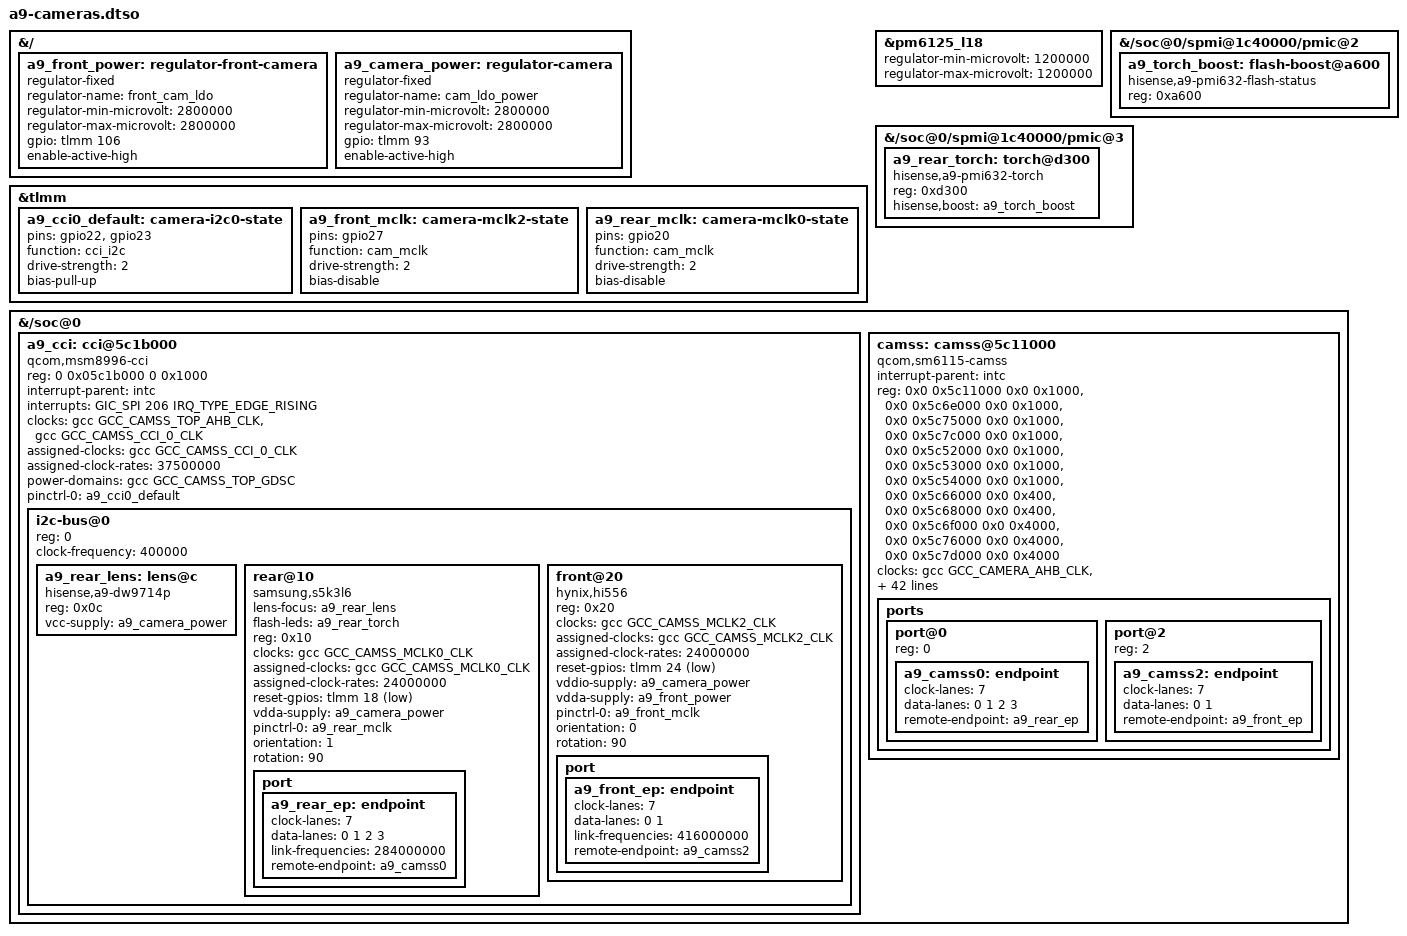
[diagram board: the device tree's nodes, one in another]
// SPDX-License-Identifier: GPL-2.0-only
/dts-v1/;
/plugin/;
#include <dt-bindings/clock/qcom,gcc-sm6115.h>
#include <dt-bindings/gpio/gpio.h>
#include <dt-bindings/interrupt-controller/arm-gic.h>
#include <dt-bindings/interconnect/qcom,sm6115.h>
#include <dt-bindings/interconnect/qcom,rpm-icc.h>

/* Default dual-sensor graph. A9_FRONT_PROBE/A9_REAR_ONLY select isolated graphs.
 * CAMSS 3PH/14nm DPHY uses data lanes 0..3 and the dedicated clock lane 7.
 * csid_get_lane_assign() consumes these positions directly (rear 0x3210).
 */
&{/} {
#ifndef A9_REAR_ONLY
 a9_front_power: regulator-front-camera {
  compatible = "regulator-fixed";
  regulator-name = "front_cam_ldo";
  /* GPIO106 supplies both analogue 2.8V and core 1.2V. */
  regulator-min-microvolt = <2800000>;
  regulator-max-microvolt = <2800000>;
  gpio = <&tlmm 106 GPIO_ACTIVE_HIGH>;
  enable-active-high;
 };
#endif
	a9_camera_power: regulator-camera {
		compatible = "regulator-fixed";
		regulator-name = "cam_ldo_power";
		/* External LDO bank supplies 1.8V I/O, 2.8V analogue/AF, 1.05V core. */
		regulator-min-microvolt = <2800000>;
		regulator-max-microvolt = <2800000>;
		gpio = <&tlmm 93 GPIO_ACTIVE_HIGH>;
		enable-active-high;
	};
};

&tlmm {
	a9_cci0_default: camera-i2c0-state {
		pins = "gpio22", "gpio23";
		function = "cci_i2c";
		drive-strength = <2>;
		bias-pull-up;
	};
	a9_front_mclk: camera-mclk2-state {
  pins = "gpio27";
  function = "cam_mclk";
  drive-strength = <2>;
  bias-disable;
 };
 a9_rear_mclk: camera-mclk0-state {
		pins = "gpio20";
		function = "cam_mclk";
		drive-strength = <2>;
		bias-disable;
	};
};

/* Stock PHY rail: PM6125 L18, camera consumer requests 1.2V. */
&pm6125_l18 {
	regulator-min-microvolt = <1200000>;
	regulator-max-microvolt = <1200000>;
};

#ifndef A9_FRONT_PROBE
&{/soc@0/spmi@1c40000/pmic@2} {
 #address-cells = <1>;
 #size-cells = <0>;
 a9_torch_boost: flash-boost@a600 {
  compatible = "hisense,a9-pmi632-flash-status";
  reg = <0xa600>;
 };
};
&{/soc@0/spmi@1c40000/pmic@3} {
 #address-cells = <1>;
 #size-cells = <0>;
 a9_rear_torch: torch@d300 {
  compatible = "hisense,a9-pmi632-torch";
  reg = <0xd300>;
  hisense,boost = <&a9_torch_boost>;
  status = "okay";
 };
};
#endif

&{/soc@0} {
	#address-cells = <2>;
	#size-cells = <2>;
	a9_cci: cci@5c1b000 {
		compatible = "qcom,msm8996-cci";
		reg = <0 0x05c1b000 0 0x1000>;
		interrupt-parent = <&intc>;
		interrupts = <GIC_SPI 206 IRQ_TYPE_EDGE_RISING>;
		clocks = <&gcc GCC_CAMSS_TOP_AHB_CLK>, <&gcc GCC_CAMSS_CCI_0_CLK>;
		clock-names = "ahb", "cci";
		assigned-clocks = <&gcc GCC_CAMSS_CCI_0_CLK>;
		assigned-clock-rates = <37500000>;
		power-domains = <&gcc GCC_CAMSS_TOP_GDSC>;
		pinctrl-names = "default";
		pinctrl-0 = <&a9_cci0_default>;
		#address-cells = <1>;
		#size-cells = <0>;
		status = "okay";
		i2c-bus@0 {
			reg = <0>;
			clock-frequency = <400000>;
			#address-cells = <1>;
			#size-cells = <0>;
#ifndef A9_FRONT_PROBE
   a9_rear_lens: lens@c {
    compatible = "hisense,a9-dw9714p";
    reg = <0x0c>;
    vcc-supply = <&a9_camera_power>;
   };
			rear@10 {
				compatible = "samsung,s5k3l6";
                lens-focus = <&a9_rear_lens>;
                flash-leds = <&a9_rear_torch>;
				reg = <0x10>;
				clocks = <&gcc GCC_CAMSS_MCLK0_CLK>;
				assigned-clocks = <&gcc GCC_CAMSS_MCLK0_CLK>;
				assigned-clock-rates = <24000000>;
				reset-gpios = <&tlmm 18 GPIO_ACTIVE_LOW>;
				vdda-supply = <&a9_camera_power>;
				pinctrl-names = "default";
				pinctrl-0 = <&a9_rear_mclk>;
				/* V4L2 front=0, back=1; the DT property wins over HAL YAML. */
				orientation = <1>;
				/* Linux CCW90 -> Android CW270, matching stock rear roll270. */
				rotation = <90>;
				port {
					a9_rear_ep: endpoint {
						clock-lanes = <7>;
						data-lanes = <0 1 2 3>;
						link-frequencies = /bits/ 64 <284000000>;
						remote-endpoint = <&a9_camss0>;
					};
				};
			};
#endif
#ifndef A9_REAR_ONLY
			front@20 {
				compatible = "hynix,hi556";
				reg = <0x20>;
				clocks = <&gcc GCC_CAMSS_MCLK2_CLK>;
				assigned-clocks = <&gcc GCC_CAMSS_MCLK2_CLK>;
				assigned-clock-rates = <24000000>;
				reset-gpios = <&tlmm 24 GPIO_ACTIVE_LOW>;
				vddio-supply = <&a9_camera_power>;
				vdda-supply = <&a9_front_power>;
				pinctrl-names = "default";
				pinctrl-0 = <&a9_front_mclk>;
				/* Front=0; Linux CCW90 gives stock Android CW270. */
				orientation = <0>;
				rotation = <90>;
				port {
					a9_front_ep: endpoint {
						clock-lanes = <7>;
						data-lanes = <0 1>;
						/* Derived from stock OP pixel rate, needs hardware proof. */
						link-frequencies = /bits/ 64 <416000000>;
						remote-endpoint = <&a9_camss2>;
					};
				};
			};
#endif
		};
	};
		camss: camss@5c11000 {
			compatible = "qcom,sm6115-camss";
			interrupt-parent = <&intc>;

			reg = <0x0 0x5c11000 0x0 0x1000>,
			      <0x0 0x5c6e000 0x0 0x1000>,
			      <0x0 0x5c75000 0x0 0x1000>,
			      <0x0 0x5c7c000 0x0 0x1000>,
			      <0x0 0x5c52000 0x0 0x1000>,
			      <0x0 0x5c53000 0x0 0x1000>,
			      <0x0 0x5c54000 0x0 0x1000>,
			      <0x0 0x5c66000 0x0 0x400>,
			      <0x0 0x5c68000 0x0 0x400>,
			      <0x0 0x5c6f000 0x0 0x4000>,
			      <0x0 0x5c76000 0x0 0x4000>,
			      <0x0 0x5c7d000 0x0 0x4000>;
			reg-names = "top", "csid0", "csid1", "csid2",
			    "csiphy0", "csiphy1", "csiphy2", "csitpg0", "csitpg1",
			    "vfe0", "vfe1", "vfe2";

			clocks = <&gcc GCC_CAMERA_AHB_CLK>,
				 <&gcc GCC_CAMSS_AXI_CLK>,
				 <&gcc GCC_CAMSS_NRT_AXI_CLK>,
				 <&gcc GCC_CAMSS_RT_AXI_CLK>,
				 <&gcc GCC_CAMSS_TFE_0_CSID_CLK>,
				 <&gcc GCC_CAMSS_TFE_1_CSID_CLK>,
				 <&gcc GCC_CAMSS_TFE_2_CSID_CLK>,
				 <&gcc GCC_CAMSS_CPHY_0_CLK>,
				 <&gcc GCC_CAMSS_CSI0PHYTIMER_CLK>,
				 <&gcc GCC_CAMSS_CPHY_1_CLK>,
				 <&gcc GCC_CAMSS_CSI1PHYTIMER_CLK>,
				 <&gcc GCC_CAMSS_CPHY_2_CLK>,
				 <&gcc GCC_CAMSS_CSI2PHYTIMER_CLK>,
				 <&gcc GCC_CAMSS_TOP_AHB_CLK>,
				 <&gcc GCC_CAMSS_TFE_0_CLK>,
				 <&gcc GCC_CAMSS_TFE_0_CPHY_RX_CLK>,
				 <&gcc GCC_CAMSS_TFE_1_CLK>,
				 <&gcc GCC_CAMSS_TFE_1_CPHY_RX_CLK>,
				 <&gcc GCC_CAMSS_TFE_2_CLK>,
				 <&gcc GCC_CAMSS_TFE_2_CPHY_RX_CLK>;
			clock-names = "ahb", "axi", "camnoc_nrt_axi", "camnoc_rt_axi",
			      "csi0", "csi1", "csi2", "csiphy0", "csiphy0_timer",
			      "csiphy1", "csiphy1_timer", "csiphy2", "csiphy2_timer",
			      "top_ahb", "vfe0", "vfe0_cphy_rx", "vfe1", "vfe1_cphy_rx",
			      "vfe2", "vfe2_cphy_rx";

			interrupts = <GIC_SPI 210 IRQ_TYPE_EDGE_RISING>,
				     <GIC_SPI 212 IRQ_TYPE_EDGE_RISING>,
				     <GIC_SPI 77 IRQ_TYPE_EDGE_RISING>,
				     <GIC_SPI 72 IRQ_TYPE_EDGE_RISING>,
				     <GIC_SPI 73 IRQ_TYPE_EDGE_RISING>,
				     <GIC_SPI 74 IRQ_TYPE_EDGE_RISING>,
				     <GIC_SPI 309 IRQ_TYPE_EDGE_RISING>,
				     <GIC_SPI 310 IRQ_TYPE_EDGE_RISING>,
				     <GIC_SPI 211 IRQ_TYPE_EDGE_RISING>,
				     <GIC_SPI 213 IRQ_TYPE_EDGE_RISING>,
				     <GIC_SPI 78 IRQ_TYPE_EDGE_RISING>;
			interrupt-names = "csid0",
					  "csid1",
					  "csid2",
					  "csiphy0",
					  "csiphy1",
					  "csiphy2",
					  "csitpg0",
					  "csitpg1",
					  "vfe0",
					  "vfe1",
					  "vfe2";

			interconnects = <&bimc MASTER_AMPSS_M0 RPM_ACTIVE_TAG
					 &config_noc SLAVE_CAMERA_CFG RPM_ACTIVE_TAG>,
					<&mmrt_virt MASTER_CAMNOC_HF RPM_ALWAYS_TAG
					 &bimc SLAVE_EBI_CH0 RPM_ALWAYS_TAG>,
					<&mmnrt_virt MASTER_CAMNOC_SF RPM_ALWAYS_TAG
					 &bimc SLAVE_EBI_CH0 RPM_ALWAYS_TAG>;
			interconnect-names = "ahb",
					     "hf_mnoc",
					     "sf_mnoc";

			iommus = <&apps_smmu 0x400 0x0>,
				 <&apps_smmu 0x800 0x0>,
				 <&apps_smmu 0x820 0x0>,
				 <&apps_smmu 0x840 0x0>;

			power-domains = <&gcc GCC_CAMSS_TOP_GDSC>;
			vdd-csiphy-1p2-supply = <&pm6125_l18>;

			status = "okay";

			ports {
				#address-cells = <1>;
				#size-cells = <0>;
#ifndef A9_FRONT_PROBE
				port@0 {
					reg = <0>;
					a9_camss0: endpoint {
						clock-lanes = <7>;
						data-lanes = <0 1 2 3>;
						remote-endpoint = <&a9_rear_ep>;
					};
				};
#endif
#ifndef A9_REAR_ONLY
				port@2 {
					reg = <2>;
					a9_camss2: endpoint {
						clock-lanes = <7>;
						data-lanes = <0 1>;
						remote-endpoint = <&a9_front_ep>;
					};
				};
#endif
			};
		};

};
